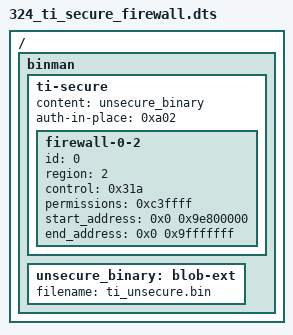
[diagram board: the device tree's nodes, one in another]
// SPDX-License-Identifier: GPL-2.0+

/dts-v1/;

/ {
	#address-cells = <1>;
	#size-cells = <1>;

	binman {
		ti-secure {
			content = <&unsecure_binary>;
			auth-in-place = <0xa02>;

			firewall-0-2 {
				id = <0>;
				region = <2>;
				control = <0x31a>;
				permissions = <0xc3ffff>;
				start_address = <0x0 0x9e800000>;
				end_address = <0x0 0x9fffffff>;
			};

		};
		unsecure_binary: blob-ext {
			filename = "ti_unsecure.bin";
		};
	};
};
